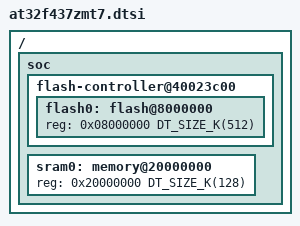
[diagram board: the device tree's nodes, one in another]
/*
 * Copyright (c) 2022 YuLong Yao <feilongphone@gmail.com>
 *
 * SPDX-License-Identifier: Apache-2.0
 */

#include <mem.h>
#include <artery/at32f43x/at32f43x.dtsi>

/ {
	soc {
		flash-controller@40023c00 {
			flash0: flash@8000000 {
				reg = <0x08000000 DT_SIZE_K(512)>;
			};
		};

		sram0: memory@20000000 {
			reg = <0x20000000 DT_SIZE_K(128)>;
		};
	};
};
